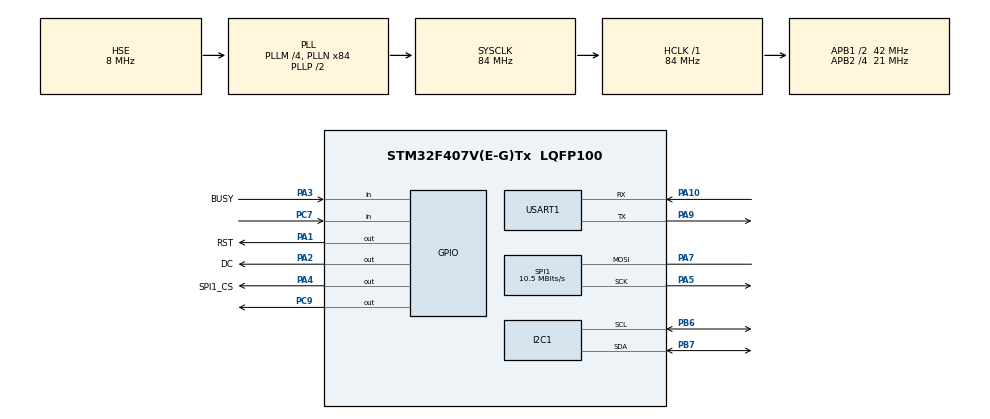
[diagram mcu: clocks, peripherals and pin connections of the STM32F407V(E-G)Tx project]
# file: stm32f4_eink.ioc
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Dma.I2C1_RX.0.Direction=DMA_PERIPH_TO_MEMORY
Dma.I2C1_RX.0.FIFOMode=DMA_FIFOMODE_DISABLE
Dma.I2C1_RX.0.Instance=DMA1_Stream0
Dma.I2C1_RX.0.MemDataAlignment=DMA_MDATAALIGN_BYTE
Dma.I2C1_RX.0.MemInc=DMA_MINC_ENABLE
Dma.I2C1_RX.0.Mode=DMA_NORMAL
Dma.I2C1_RX.0.PeriphDataAlignment=DMA_PDATAALIGN_BYTE
Dma.I2C1_RX.0.PeriphInc=DMA_PINC_DISABLE
Dma.I2C1_RX.0.Priority=DMA_PRIORITY_LOW
Dma.Request0=I2C1_RX
FREERTOS.INCLUDE_uxTaskGetStackHighWaterMark=1
FREERTOS.Mutexes01=I2CSerialCommandMux,Dynamic,NULL;SPIDisplayMix,Dynamic,NULL
FREERTOS.Tasks01=defaultTask,-3,128,StartDefaultTask,Default,NULL,Dynamic,NULL,NULL;drawTask,-3,1000,StartDrawTask,As external,NULL,Dynamic,NULL,NULL;serialCmdTask,0,1000,StartSerialCmdTask,As external,NULL,Dynamic,NULL,NULL
FREERTOS.configTOTAL_HEAP_SIZE=64000
FREERTOS.configUSE_COUNTING_SEMAPHORES=1
I2C1.AddressingMode=I2C_ADDRESSINGMODE_7BIT
I2C1.OwnAddress=0x03
Mcu.Family=STM32F4
Mcu.Name=STM32F407V(E-G)Tx
Mcu.Package=LQFP100
NVIC.DMA1_Stream0_IRQn=true\:5\:0\:false\:false\:true\:true\:false
NVIC.I2C1_ER_IRQn=true\:5\:0\:false\:true\:true\:1\:true\:true
NVIC.I2C1_EV_IRQn=true\:5\:0\:false\:false\:true\:true\:true
NVIC.PriorityGroup=NVIC_PRIORITYGROUP_4
NVIC.RTC_WKUP_IRQn=true\:5\:0\:false\:false\:true\:true\:true
NVIC.TIM1_UP_TIM10_IRQn=true\:0\:0\:false\:false\:true\:false\:false
NVIC.TimeBase=TIM1_UP_TIM10_IRQn
NVIC.TimeBaseIP=TIM1
PA1.GPIO_Label=RST
PA1.Signal=GPIO_Output
PA10.Mode=Asynchronous
PA10.Signal=USART1_RX
PA2.GPIO_Label=DC
PA2.Signal=GPIO_Output
PA3.GPIO_Label=BUSY
PA3.Signal=GPIO_Input
PA4.GPIO_Label=SPI1_CS
PA4.Signal=GPIO_Output
PA5.Mode=Simplex_Bidirectional_Master
PA5.Signal=SPI1_SCK
PA7.Mode=Simplex_Bidirectional_Master
PA7.Signal=SPI1_MOSI
PA9.Mode=Asynchronous
PA9.Signal=USART1_TX
PB6.GPIO_PuPdOD=GPIO_PULLUP
PB6.Mode=I2C
PB6.Signal=I2C1_SCL
PB7.GPIO_PuPdOD=GPIO_PULLUP
PB7.Mode=I2C
PB7.Signal=I2C1_SDA
PC7.Signal=GPIO_Input
PC9.GPIO_PuPd=GPIO_PULLUP
PC9.Signal=GPIO_Output
PH0-OSC_IN.Mode=HSE-External-Oscillator
PH0-OSC_IN.Signal=RCC_OSC_IN
PH1-OSC_OUT.Mode=HSE-External-Oscillator
PH1-OSC_OUT.Signal=RCC_OSC_OUT
ProjectManager.HeapSize=0x600
ProjectManager.StackSize=0x800
ProjectManager.TargetToolchain=Other Toolchains (GPDSC)
RCC.48MHZClocksFreq_Value=42000000
RCC.AHBFreq_Value=84000000
RCC.APB1CLKDivider=RCC_HCLK_DIV2
RCC.APB1Freq_Value=42000000
RCC.APB1TimFreq_Value=84000000
RCC.APB2CLKDivider=RCC_HCLK_DIV4
RCC.APB2Freq_Value=21000000
RCC.APB2TimFreq_Value=42000000
RCC.CortexFreq_Value=84000000
RCC.HCLKFreq_Value=84000000
RCC.HSE_VALUE=8000000
RCC.HSI_VALUE=16000000
RCC.LSE_VALUE=32768
RCC.PLLM=4
RCC.PLLN=84
RCC.PLLSourceVirtual=RCC_PLLSOURCE_HSE
RCC.SYSCLKFreq_VALUE=84000000
RCC.SYSCLKSource=RCC_SYSCLKSOURCE_PLLCLK
RCC.VCOOutputFreq_Value=168000000
RTC.WakeUpClock=RTC_WAKEUPCLOCK_RTCCLK_DIV16
RTC.WakeUpCounter=65535
SPI1.BaudRatePrescaler=SPI_BAUDRATEPRESCALER_2
SPI1.CalculateBaudRate=10.5 MBits/s
SPI1.Direction=SPI_DIRECTION_1LINE
SPI1.Mode=SPI_MODE_MASTER
SPI1.VirtualType=VM_MASTER
USART1.VirtualMode=VM_ASYNC
VP_FREERTOS_VS_ENABLE.Mode=Enabled
VP_RTC_VS_RTC_Activate.Mode=RTC_Enabled
VP_RTC_VS_RTC_Calendar.Mode=RTC_Calendar
VP_RTC_VS_RTC_WakeUp_intern.Mode=WakeUp
VP_SYS_VS_tim1.Mode=TIM1
board=custom

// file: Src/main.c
/**
  ******************************************************************************
  * @file           : main.c
  * @brief          : Main program body
  ******************************************************************************
  * This notice applies to any and all portions of this file
  * that are not between comment pairs USER CODE BEGIN and
  * USER CODE END. Other portions of this file, whether
  * inserted by the user or by software development tools
  * are owned by their respective copyright owners.
  *
  * Copyright (c) 2018 STMicroelectronics International N.V.
  * All rights reserved.
  *
  * Redistribution and use in source and binary forms, with or without
  * modification, are permitted, provided that the following conditions are met:
  *
  * 1. Redistribution of source code must retain the above copyright notice,
  *    this list of conditions and the following disclaimer.
  * 2. Redistributions in binary form must reproduce the above copyright notice,
  *    this list of conditions and the following disclaimer in the documentation
  *    and/or other materials provided with the distribution.
  * 3. Neither the name of STMicroelectronics nor the names of other
  *    contributors to this software may be used to endorse or promote products
  *    derived from this software without specific written permission.
  * 4. This software, including modifications and/or derivative works of this
  *    software, must execute solely and exclusively on microcontroller or
  *    microprocessor devices manufactured by or for STMicroelectronics.
  * 5. Redistribution and use of this software other than as permitted under
  *    this license is void and will automatically terminate your rights under
  *    this license.
  *
  * THIS SOFTWARE IS PROVIDED BY STMICROELECTRONICS AND CONTRIBUTORS "AS IS"
  * AND ANY EXPRESS, IMPLIED OR STATUTORY WARRANTIES, INCLUDING, BUT NOT
  * LIMITED TO, THE IMPLIED WARRANTIES OF MERCHANTABILITY, FITNESS FOR A
  * PARTICULAR PURPOSE AND NON-INFRINGEMENT OF THIRD PARTY INTELLECTUAL PROPERTY
  * RIGHTS ARE DISCLAIMED TO THE FULLEST EXTENT PERMITTED BY LAW. IN NO EVENT
  * SHALL STMICROELECTRONICS OR CONTRIBUTORS BE LIABLE FOR ANY DIRECT, INDIRECT,
  * INCIDENTAL, SPECIAL, EXEMPLARY, OR CONSEQUENTIAL DAMAGES (INCLUDING, BUT NOT
  * LIMITED TO, PROCUREMENT OF SUBSTITUTE GOODS OR SERVICES; LOSS OF USE, DATA,
  * OR PROFITS; OR BUSINESS INTERRUPTION) HOWEVER CAUSED AND ON ANY THEORY OF
  * LIABILITY, WHETHER IN CONTRACT, STRICT LIABILITY, OR TORT (INCLUDING
  * NEGLIGENCE OR OTHERWISE) ARISING IN ANY WAY OUT OF THE USE OF THIS SOFTWARE,
  * EVEN IF ADVISED OF THE POSSIBILITY OF SUCH DAMAGE.
  *
  ******************************************************************************
  */
#include "main.h"
#include "stm32f4xx_hal.h"
#include "cmsis_os.h"

/* USER CODE BEGIN Includes */
#include "application.h"
/* USER CODE END Includes */

I2C_HandleTypeDef hi2c1;
DMA_HandleTypeDef hdma_i2c1_rx;

RTC_HandleTypeDef hrtc;

SPI_HandleTypeDef hspi1;

UART_HandleTypeDef huart1;

osThreadId defaultTaskHandle;
osThreadId drawTaskHandle;
osThreadId serialCmdTaskHandle;
osMutexId I2CSerialCommandMuxHandle;
osMutexId SPIDisplayMixHandle;

/* USER CODE BEGIN PV */
/* Private variables ---------------------------------------------------------*/
volatile int next_msg_length;
/* USER CODE END PV */

void SystemClock_Config(void);
static void MX_GPIO_Init(void);
static void MX_DMA_Init(void);
static void MX_SPI1_Init(void);
static void MX_USART1_UART_Init(void);
static void MX_I2C1_Init(void);
static void MX_RTC_Init(void);
void StartDefaultTask(void const * argument);
extern void StartDrawTask(void const * argument);
extern void StartSerialCmdTask(void const * argument);
static void MX_NVIC_Init(void);

/* USER CODE BEGIN PFP */
/* Private function prototypes -----------------------------------------------*/

/* USER CODE END PFP */

int main(void)
{

  /* MCU Configuration----------------------------------------------------------*/

  /* Reset of all peripherals, Initializes the Flash interface and the Systick. */
  HAL_Init();

  /* Configure the system clock */
  SystemClock_Config();

  /* Initialize all configured peripherals */
  MX_GPIO_Init();
  MX_DMA_Init();
  MX_SPI1_Init();
  MX_USART1_UART_Init();
  MX_I2C1_Init();
  MX_RTC_Init();

  /* Initialize interrupts */
  MX_NVIC_Init();

  /* Create the mutex(es) */
  /* definition and creation of I2CSerialCommandMux */
  osMutexDef(I2CSerialCommandMux);
  I2CSerialCommandMuxHandle = osMutexCreate(osMutex(I2CSerialCommandMux));

  /* definition and creation of SPIDisplayMix */
  osMutexDef(SPIDisplayMix);
  SPIDisplayMixHandle = osMutexCreate(osMutex(SPIDisplayMix));

  /* Create the thread(s) */
  /* definition and creation of defaultTask */
  osThreadDef(defaultTask, StartDefaultTask, osPriorityIdle, 0, 128);
  defaultTaskHandle = osThreadCreate(osThread(defaultTask), NULL);

  /* definition and creation of drawTask */
  osThreadDef(drawTask, StartDrawTask, osPriorityIdle, 0, 1000);
  drawTaskHandle = osThreadCreate(osThread(drawTask), NULL);

  /* definition and creation of serialCmdTask */
  osThreadDef(serialCmdTask, StartSerialCmdTask, osPriorityNormal, 0, 1000);
  serialCmdTaskHandle = osThreadCreate(osThread(serialCmdTask), NULL);

  /* Start scheduler */
  osKernelStart();

  /* We should never get here as control is now taken by the scheduler */

  /* Infinite loop */
  while (1)
  {

  }

}

void SystemClock_Config(void)
{

  RCC_OscInitTypeDef RCC_OscInitStruct;
  RCC_ClkInitTypeDef RCC_ClkInitStruct;
  RCC_PeriphCLKInitTypeDef PeriphClkInitStruct;

    /**Configure the main internal regulator output voltage
    */
  __HAL_RCC_PWR_CLK_ENABLE();

  __HAL_PWR_VOLTAGESCALING_CONFIG(PWR_REGULATOR_VOLTAGE_SCALE1);

    /**Initializes the CPU, AHB and APB busses clocks
    */
  RCC_OscInitStruct.OscillatorType = RCC_OSCILLATORTYPE_LSI|RCC_OSCILLATORTYPE_HSE;
  RCC_OscInitStruct.HSEState = RCC_HSE_ON;
  RCC_OscInitStruct.LSIState = RCC_LSI_ON;
  RCC_OscInitStruct.PLL.PLLState = RCC_PLL_ON;
  RCC_OscInitStruct.PLL.PLLSource = RCC_PLLSOURCE_HSE;
  RCC_OscInitStruct.PLL.PLLM = 4;
  RCC_OscInitStruct.PLL.PLLN = 84;
  RCC_OscInitStruct.PLL.PLLP = RCC_PLLP_DIV2;
  RCC_OscInitStruct.PLL.PLLQ = 4;
  if (HAL_RCC_OscConfig(&RCC_OscInitStruct) != HAL_OK)
  {
    _Error_Handler(__FILE__, __LINE__);
  }

    /**Initializes the CPU, AHB and APB busses clocks
    */
  RCC_ClkInitStruct.ClockType = RCC_CLOCKTYPE_HCLK|RCC_CLOCKTYPE_SYSCLK
                              |RCC_CLOCKTYPE_PCLK1|RCC_CLOCKTYPE_PCLK2;
  RCC_ClkInitStruct.SYSCLKSource = RCC_SYSCLKSOURCE_PLLCLK;
  RCC_ClkInitStruct.AHBCLKDivider = RCC_SYSCLK_DIV1;
  RCC_ClkInitStruct.APB1CLKDivider = RCC_HCLK_DIV2;
  RCC_ClkInitStruct.APB2CLKDivider = RCC_HCLK_DIV4;

  if (HAL_RCC_ClockConfig(&RCC_ClkInitStruct, FLASH_LATENCY_2) != HAL_OK)
  {
    _Error_Handler(__FILE__, __LINE__);
  }

  PeriphClkInitStruct.PeriphClockSelection = RCC_PERIPHCLK_RTC;
  PeriphClkInitStruct.RTCClockSelection = RCC_RTCCLKSOURCE_LSI;
  if (HAL_RCCEx_PeriphCLKConfig(&PeriphClkInitStruct) != HAL_OK)
  {
    _Error_Handler(__FILE__, __LINE__);
  }

    /**Configure the Systick interrupt time
    */
  HAL_SYSTICK_Config(HAL_RCC_GetHCLKFreq()/1000);

    /**Configure the Systick
    */
  HAL_SYSTICK_CLKSourceConfig(SYSTICK_CLKSOURCE_HCLK);

  /* SysTick_IRQn interrupt configuration */
  HAL_NVIC_SetPriority(SysTick_IRQn, 15, 0);
}

/**
  * @brief NVIC Configuration.
  * @retval None
  */
static void MX_NVIC_Init(void)
{
  /* I2C1_ER_IRQn interrupt configuration */
  HAL_NVIC_SetPriority(I2C1_ER_IRQn, 5, 0);
  HAL_NVIC_EnableIRQ(I2C1_ER_IRQn);
}

/* I2C1 init function */
static void MX_I2C1_Init(void)
{

  hi2c1.Instance = I2C1;
  hi2c1.Init.ClockSpeed = 100000;
  hi2c1.Init.DutyCycle = I2C_DUTYCYCLE_2;
  hi2c1.Init.OwnAddress1 = 6;
  hi2c1.Init.AddressingMode = I2C_ADDRESSINGMODE_7BIT;
  hi2c1.Init.DualAddressMode = I2C_DUALADDRESS_DISABLE;
  hi2c1.Init.OwnAddress2 = 0;
  hi2c1.Init.GeneralCallMode = I2C_GENERALCALL_DISABLE;
  hi2c1.Init.NoStretchMode = I2C_NOSTRETCH_DISABLE;
  if (HAL_I2C_Init(&hi2c1) != HAL_OK)
  {
    _Error_Handler(__FILE__, __LINE__);
  }

}

/* RTC init function */
static void MX_RTC_Init(void)
{

  RTC_TimeTypeDef sTime;
  RTC_DateTypeDef sDate;

    /**Initialize RTC Only
    */
  hrtc.Instance = RTC;
  hrtc.Init.HourFormat = RTC_HOURFORMAT_24;
  hrtc.Init.AsynchPrediv = 127;
  hrtc.Init.SynchPrediv = 255;
  hrtc.Init.OutPut = RTC_OUTPUT_DISABLE;
  hrtc.Init.OutPutPolarity = RTC_OUTPUT_POLARITY_HIGH;
  hrtc.Init.OutPutType = RTC_OUTPUT_TYPE_OPENDRAIN;
  if (HAL_RTC_Init(&hrtc) != HAL_OK)
  {
    _Error_Handler(__FILE__, __LINE__);
  }

    /**Initialize RTC and set the Time and Date
    */
  sTime.Hours = 0x0;
  sTime.Minutes = 0x0;
  sTime.Seconds = 0x0;
  sTime.DayLightSaving = RTC_DAYLIGHTSAVING_NONE;
  sTime.StoreOperation = RTC_STOREOPERATION_RESET;
  if (HAL_RTC_SetTime(&hrtc, &sTime, RTC_FORMAT_BCD) != HAL_OK)
  {
    _Error_Handler(__FILE__, __LINE__);
  }

  sDate.WeekDay = RTC_WEEKDAY_MONDAY;
  sDate.Month = RTC_MONTH_JANUARY;
  sDate.Date = 0x1;
  sDate.Year = 0x0;

  if (HAL_RTC_SetDate(&hrtc, &sDate, RTC_FORMAT_BCD) != HAL_OK)
  {
    _Error_Handler(__FILE__, __LINE__);
  }

    /**Enable the WakeUp
    */
  if (HAL_RTCEx_SetWakeUpTimer_IT(&hrtc, 65535, RTC_WAKEUPCLOCK_RTCCLK_DIV16) != HAL_OK)
  {
    _Error_Handler(__FILE__, __LINE__);
  }

}

/* SPI1 init function */
static void MX_SPI1_Init(void)
{

  /* SPI1 parameter configuration*/
  hspi1.Instance = SPI1;
  hspi1.Init.Mode = SPI_MODE_MASTER;
  hspi1.Init.Direction = SPI_DIRECTION_1LINE;
  hspi1.Init.DataSize = SPI_DATASIZE_8BIT;
  hspi1.Init.CLKPolarity = SPI_POLARITY_LOW;
  hspi1.Init.CLKPhase = SPI_PHASE_1EDGE;
  hspi1.Init.NSS = SPI_NSS_SOFT;
  hspi1.Init.BaudRatePrescaler = SPI_BAUDRATEPRESCALER_2;
  hspi1.Init.FirstBit = SPI_FIRSTBIT_MSB;
  hspi1.Init.TIMode = SPI_TIMODE_DISABLE;
  hspi1.Init.CRCCalculation = SPI_CRCCALCULATION_DISABLE;
  hspi1.Init.CRCPolynomial = 10;
  if (HAL_SPI_Init(&hspi1) != HAL_OK)
  {
    _Error_Handler(__FILE__, __LINE__);
  }

}

/* USART1 init function */
static void MX_USART1_UART_Init(void)
{

  huart1.Instance = USART1;
  huart1.Init.BaudRate = 115200;
  huart1.Init.WordLength = UART_WORDLENGTH_8B;
  huart1.Init.StopBits = UART_STOPBITS_1;
  huart1.Init.Parity = UART_PARITY_NONE;
  huart1.Init.Mode = UART_MODE_TX_RX;
  huart1.Init.HwFlowCtl = UART_HWCONTROL_NONE;
  huart1.Init.OverSampling = UART_OVERSAMPLING_16;
  if (HAL_UART_Init(&huart1) != HAL_OK)
  {
    _Error_Handler(__FILE__, __LINE__);
  }

}

static void MX_DMA_Init(void)
{
  /* DMA controller clock enable */
  __HAL_RCC_DMA1_CLK_ENABLE();

  /* DMA interrupt init */
  /* DMA1_Stream0_IRQn interrupt configuration */
  HAL_NVIC_SetPriority(DMA1_Stream0_IRQn, 5, 0);
  HAL_NVIC_EnableIRQ(DMA1_Stream0_IRQn);

}

/** Configure pins as
        * Analog
        * Input
        * Output
        * EVENT_OUT
        * EXTI
*/
static void MX_GPIO_Init(void)
{

  GPIO_InitTypeDef GPIO_InitStruct;

  /* GPIO Ports Clock Enable */
  __HAL_RCC_GPIOH_CLK_ENABLE();
  __HAL_RCC_GPIOA_CLK_ENABLE();
  __HAL_RCC_GPIOC_CLK_ENABLE();
  __HAL_RCC_GPIOB_CLK_ENABLE();

  /*Configure GPIO pin Output Level */
  HAL_GPIO_WritePin(GPIOA, RST_Pin|DC_Pin|SPI1_CS_Pin, GPIO_PIN_RESET);

  /*Configure GPIO pin Output Level */
  HAL_GPIO_WritePin(GPIOC, GPIO_PIN_9, GPIO_PIN_RESET);

  /*Configure GPIO pins : RST_Pin DC_Pin SPI1_CS_Pin */
  GPIO_InitStruct.Pin = RST_Pin|DC_Pin|SPI1_CS_Pin;
  GPIO_InitStruct.Mode = GPIO_MODE_OUTPUT_PP;
  GPIO_InitStruct.Pull = GPIO_NOPULL;
  GPIO_InitStruct.Speed = GPIO_SPEED_FREQ_LOW;
  HAL_GPIO_Init(GPIOA, &GPIO_InitStruct);

  /*Configure GPIO pin : BUSY_Pin */
  GPIO_InitStruct.Pin = BUSY_Pin;
  GPIO_InitStruct.Mode = GPIO_MODE_INPUT;
  GPIO_InitStruct.Pull = GPIO_NOPULL;
  HAL_GPIO_Init(BUSY_GPIO_Port, &GPIO_InitStruct);

  /*Configure GPIO pin : PC7 */
  GPIO_InitStruct.Pin = GPIO_PIN_7;
  GPIO_InitStruct.Mode = GPIO_MODE_INPUT;
  GPIO_InitStruct.Pull = GPIO_NOPULL;
  HAL_GPIO_Init(GPIOC, &GPIO_InitStruct);

  /*Configure GPIO pin : PC9 */
  GPIO_InitStruct.Pin = GPIO_PIN_9;
  GPIO_InitStruct.Mode = GPIO_MODE_OUTPUT_PP;
  GPIO_InitStruct.Pull = GPIO_PULLUP;
  GPIO_InitStruct.Speed = GPIO_SPEED_FREQ_LOW;
  HAL_GPIO_Init(GPIOC, &GPIO_InitStruct);

}

/* StartDefaultTask function */
void StartDefaultTask(void const * argument)
{

  /* USER CODE BEGIN 5 */
	Application.run();
  /* Infinite loop */
  for(;;)
  {
    osDelay(1);
  }
  /* USER CODE END 5 */
}

void HAL_TIM_PeriodElapsedCallback(TIM_HandleTypeDef *htim)
{
  if (htim->Instance == TIM1) {
    HAL_IncTick();
  }
}

void _Error_Handler(char *file, int line)
{
  while(1)
  {
  }
}

/************************ (C) COPYRIGHT STMicroelectronics *****END OF FILE****/
